VERSION ""

NS_ :

BS_:

BU_: ADTF
VAL_TABLE_ State_RPA_START_SCcnt1 171 "FS_RPA_LISTEN_MSG_CHECK" 107 "FS_RPA_LISTEN_KG_ENABLE" 59 "FS_RPA_PAIRING_SC" 51 "FS_RPA_LISTEN_TERMINATED_SC" 43 "FS_RPA_LISTEN_SC" 35 "FS_RPA_IDLE_SC" 27 "FS_RPA_IDLE_OUTSIDE_WAIT" 19 "FS_RPA_DIALOG_SC" 11 "FS_RPA_ACTIVATED_SC" 5 "FS_DefaultOf_RPA_START_SCst2" 2 "FS_STATE_22st4" 1 "FS_RPA_START_SCst2" 0 "FS_Chart_RPA_START_SC" ;
VAL_TABLE_ State_RPA_INSIDE_ACTIVE_SC 1931 "DefaultOf_RPA_ACTIV_MAN_FROM_INS" 1675 "FS_RPA_INSIDE_UNDO_CONTINUE" 1419 "FS_RPA_INSIDE_ACTIVE_UNDO" 1163 "FS_RPA_INSIDE_ACTIVE_TAKE_OVER" 907 "FS_RPA_INSIDE_ACTIVE_RECONNECT" 651 "FS_RPA_INSIDE_ACTIVE_MANEUVER_SC" 395 "FS_RPA_INSIDE_ACTIVE_CONTINUE_SC" 203 "RPA_WAIT_EIS_ACTIVATION_FROM_INS" 155 "FS_RPA_MENU_INSIDE_MANEUVER" 139 "RPA_ACTIVATE_MANEUVER_FROM_IN" 91 "FS_RPA_MENU_ADJUST_START" 75 "FS_RPA_ACTIVATE_EIS_FROM_INSIDE" 51 "FS_RPA_WAIT_INSIDE_SC" 43 "FS_RPA_UNDO_INSIDE_GET_P2_READY" 35 "FS_RPA_PARK_INSIDE_SC" 27 "FS_RPA_MENU_INSIDE_SC" 19 "FS_RPA_INSIDE_UNDO_WAIT" 11 "FS_RPA_INIT_INSIDE_SC" 5 "FS_DefaultOf_RPA_ACTIVE_FROM_INS" 3 "FS_STATE_22st5" 1 "FS_RPA_ACTIVE_FROM_INSIDE" 0 "FS_Chart_RPA_INSIDE_ACTIVE_SC" ;
VAL_TABLE_ RPA_OUTSIDE_ACTIVE_SC 1675 "Default_RPA_ACTIV_MANEU_FR_OUT" 1419 "FS_RPA_OUTSIDE_UNDO_CONTINUE" 1163 "FS_RPA_OUTSIDE_CONTINUE_SC" 907 "FS_RPA_OUTSIDE_ACTIVE_UNDO" 651 "FS_RPA_OUTSIDE_ACTIVE_RECONNECT" 395 "FS_RPA_OUTSIDE_ACTIVE_MANEUVER" 201 "FS_RPA_WAIT_EIS_ACTIV_FROM_OUT" 179 "FS_WAIT_OUTSIDE_RDY" 139 "RPA_ACTIVATE_MANEUVER_FROM_OUTS" 115 "FS_WAIT_OUTSIDE_PADH" 75 "FS_RPA_ACTIVATE_EIS_FROM_OUTSIDE" 51 "FS_RPA_WAIT_OUSIDE" 43 "FS_RPA_UNDO_OUTSIDE_GET_P2_READY" 35 "FS_RPA_PARK_OUTSIDE_SC" 27 "FS_RPA_OUTSIDE_UNDO_WAIT" 19 "FS_RPA_MENU_OUTSIDE_SC" 11 "FS_RPA_INIT_OUTSIDE_SC" 5 "FS_DefaultOf_RPA_ACTIVE_FROM_OUT" 3 "FS_STATE_20st6" 1 "FS_RPA_ACTIVE_FROM_OUTSIDE" 0 "FS_Chart_RPA_OUTSIDE_ACTIVE_SC" ;
VAL_TABLE_ currentState_RPA_END_SCcnt1 955 "FS_RPA_WAIT_P2_TERMINATE" 827 "FS_RPA_WAIT_P2_STEERING_FINISH" 699 "FS_RPA_WAIT_P2_ABORT" 571 "FS_RPA_NO_CONTINUE" 443 "FS_RPA_NORMAL_TERMINATE" 315 "FS_RPA_MANEUVER_TERMINATE" 267 "FS_RPA_CANCEL_STEERING_AND_BRAKE" 187 "FS_RPA_ERROR_TERMINATE" 139 "FS_RPA_CANCEL_EIS" 67 "FS_RPA_WAS_ACTIVE" 59 "FS_RPA_TERMINATE_SC" 51 "FS_RPA_RECONNECT_POSSIBLE" 43 "FS_RPA_KG_FINISH" 27 "FS_RPA_EIS_FINISH" 19 "FS_RPA_CONTINUE_POSSIBLE" 17 "FS_RPA_CANCEL_SC" 5 "FS_DefaultOf_RPA_END_SCst2" 3 "FS_STATE_29st3" 1 "FS_RPA_END_SCst2" 0 "FS_Chart_RPA_END_SC" ;
VAL_TABLE_ Tbl_ACTL_RemCtrlPark_Maneuver3 17 "RTE_PARK_INVALID" 16 "RTE_EXPLORATION_MODE" 15 "RTE_PARK_OUT_PERP_LEFT_BACKWARD" 14 "RTE_PARK_OUT_PERP_LEFT_FORWARD" 13 "RTE_PARK_OUT_PERP_RIGHT_BACKWARD" 12 "RTE_PARK_OUT_PERP_RIGHT_FORWARD" 11 "RTE_PARK_OUT_PARA_LEFT_BACKWARD" 10 "RTE_PARK_OUT_PARA_LEFT_FORWARD" 9 "RTE_PARK_OUT_PARA_RIGHT_BACKWARD" 8 "RTE_PARK_OUT_PARA_RIGHT_FORWARD" 7 "RTE_PARK_IN_PERP_LEFT_BACWARD" 6 "RTE_PARK_IN_PERP_LEFT_FORWARD" 5 "RTE_PARK_IN_PERP_RIGHT_BACKWARD" 4 "RTE_PARK_IN_PERP_RIGHT_FORWARD" 3 "RTE_PARK_IN_PARA_LEFT_BACKWARD" 2 "RTE_PARK_IN_PARA_LEFT_FORWARD" 1 "RTE_PARK_IN_PARA_RIGHT_BACKWARD" 0 "RTE_PARK_IN_PARA_RIGHT_FORWARD" ;
VAL_TABLE_ Tbl_ACTL_RemCtrlPark_Maneuver2 17 "RTE_PARK_INVALID" 16 "RTE_EXPLORATION_MODE" 15 "RTE_PARK_OUT_PERP_LEFT_BACKWARD" 14 "RTE_PARK_OUT_PERP_LEFT_FORWARD" 13 "RTE_PARK_OUT_PERP_RIGHT_BACKWARD" 12 "RTE_PARK_OUT_PERP_RIGHT_FORWARD" 11 "RTE_PARK_OUT_PARA_LEFT_BACKWARD" 10 "RTE_PARK_OUT_PARA_LEFT_FORWARD" 9 "RTE_PARK_OUT_PARA_RIGHT_BACKWARD" 8 "RTE_PARK_OUT_PARA_RIGHT_FORWARD" 7 "RTE_PARK_IN_PERP_LEFT_BACWARD" 6 "RTE_PARK_IN_PERP_LEFT_FORWARD" 5 "RTE_PARK_IN_PERP_RIGHT_BACKWARD" 4 "RTE_PARK_IN_PERP_RIGHT_FORWARD" 3 "RTE_PARK_IN_PARA_LEFT_BACKWARD" 2 "RTE_PARK_IN_PARA_LEFT_FORWARD" 1 "RTE_PARK_IN_PARA_RIGHT_BACKWARD" 0 "RTE_PARK_IN_PARA_RIGHT_FORWARD" ;
VAL_TABLE_ Tbl_ACTL_RemCtrlPark_Maneuvers 17 "RTE_PARK_INVALID" 16 "RTE_EXPLORATION_MODE" 15 "RTE_PARK_OUT_PERP_LEFT_BACKWARD" 14 "RTE_PARK_OUT_PERP_LEFT_FORWARD" 13 "RTE_PARK_OUT_PERP_RIGHT_BACKWARD" 12 "RTE_PARK_OUT_PERP_RIGHT_FORWARD" 11 "RTE_PARK_OUT_PARA_LEFT_BACKWARD" 10 "RTE_PARK_OUT_PARA_LEFT_FORWARD" 9 "RTE_PARK_OUT_PARA_RIGHT_BACKWARD" 8 "RTE_PARK_OUT_PARA_RIGHT_FORWARD" 7 "RTE_PARK_IN_PERP_LEFT_BACWARD" 6 "RTE_PARK_IN_PERP_LEFT_FORWARD" 5 "RTE_PARK_IN_PERP_RIGHT_BACKWARD" 4 "RTE_PARK_IN_PERP_RIGHT_FORWARD" 3 "RTE_PARK_IN_PARA_LEFT_BACKWARD" 2 "RTE_PARK_IN_PARA_LEFT_FORWARD" 1 "RTE_PARK_IN_PARA_RIGHT_BACKWARD" 0 "RTE_PARK_IN_PARA_RIGHT_FORWARD" ;
VAL_TABLE_ Tbl_ACTL_RemCtrlPark_MsgID 31 "RTE_MSG_TARGET_POS_CORRECT" 30 "RTE_MSG_OLD_APP_VER" 29 "RTE_MSG_OLD_APP_VER_3" 28 "RTE_MSG_OLD_APP_VER_2" 27 "RTE_MSG_OLD_APP_VER_1" 26 "RTE_MSG_WRONG_APP_VER_0" 25 "RTE_MSG_INCOMP" 24 "RTE_MSG_COM_NO_AUTH" 23 "RTE_MSG_COM_ERR" 22 "RTE_MSG_COM_NO_DEV" 21 "RTE_MSG_COM_NO_BT" 20 "RTE_MSG_COM_BT_OFF" 19 "RTE_MSG_NARROW_DIST" 18 "RTE_MSG_BATTERY" 17 "RTE_MSG_TRAILER" 16 "RTE_MSG_OBSTACLE" 15 "RTE_MSG_SLOPE" 14 "RTE_MSG_ASR" 13 "RTE_MSG_NO_P" 12 "RTE_MSG_ACT_DRV" 11 "RTE_MSG_DOOR_OPENED" 10 "RTE_MSG_BELT_LOCKED" 9 "RTE_MSG_KEY_ACTUATED" 8 "RTE_MSG_KEY_INSIDE_DETECTED" 7 "RTE_MSG_KEY_NOT_DETECTED" 6 "RTE_MSG_CONNECT_ERROR" 5 "RTE_MSG_SYS_ERROR" 4 "RTE_MSG_END_TURN_REACHED" 3 "RTE_MSG_MAX_DIST" 2 "RTE_MSG_TARGET_POS_REACHED" 1 "RTE_MSG_RPA_TERMINATED" 0 "RTE_MSG_NONE" ;
VAL_TABLE_ Tbl_ACTL_RemCtrlPark_CurrGear 8 "RTE_RMC_GEAR_PARK" 7 "RTE_RMC_GEAR_REVERSE" 6 "RTE_RMC_GEAR_NEUTRAL" 5 "RTE_RMC_GEAR_DRIVE" 0 "RTE_RMC_GEAR_IDLE" ;
VAL_TABLE_ Tbl_ACTL_RemCtrlP_CurrRpaMode 9 "RTE_RPA_TERMINATING" 8 "RTE_RPA_CANCEL" 7 "RTE_RPA_PARK" 6 "RTE_RPA_MENU" 5 "RTE_RPA_INIT" 4 "RTE_RPA_WAIT" 3 "RTE_RPA_LISTEN" 2 "RTE_RPA_DIALOG" 1 "RTE_RPA_PAIRING" 0 "RTE_RPA_IDLE" ;
VAL_TABLE_ Tbl_LastRcFrameType 255 "RTE_RMC_RC_FRAME_UNKNOW " 5 "RTE_RMC_RC_FRAME_DEVICE_NAME " 4 "RTE_RMC_RC_FRAME_ERROR " 3 "RTE_RMC_RC_FRAME_ACTIVE " 2 "RTE_RMC_RC_FRAME_SW_VER" 1 "RTE_RMC_RC_FRAME_HW_VER " 0 "RTE_RMC_RC_FRAME_SECURITY " ;
VAL_TABLE_ Tbl_IsRmcActive 3 "RTE_RMC_BLE_RECEIVER_PAIRING " 2 "RTE_RMC_BLE_RECEIVER_CONNECTED" 1 "RTE_RMC_BLE_RECEIVER_ACTIVE " 0 "RTE_RMC_BLE_RECEIVER_NOT_ACTIVE " ;
VAL_TABLE_ Tbl_RMC_GestureState 170 "RTE_RMC_GESTURE_ST_VALID" 85 "RTE_RMC_GESTURE_ST_NOT_VALID " ;
VAL_TABLE_ Tbl_RMC_SelectedGear 8 "RTE_RMC_GEAR_PARK " 7 "RTE_RMC_GEAR_REVERSE " 6 "RTE_RMC_GEAR_NEUTRAL " 5 "RTE_RMC_GEAR_DRIVE " 0 "RTE_RMC_GEAR_IDLE " ;
VAL_TABLE_ Tbl_RMC_DeadManSwitch 170 "RTE_RMC_DMS_ST_VALID " 85 "RTE_RMC_DMS_ST_NOT_VALID" ;
VAL_TABLE_ Tbl_RmcState 9 "RTE_RMC_APP_ST_ERROR " 8 "RTE_RMC_APP_ST_TERMINATING" 7 "RTE_RMC_APP_ST_MESSAGE " 6 "RTE_RMC_APP_ST_PARK " 5 "RTE_RMC_APP_ST_INTERRUPT " 4 "RTE_RMC_APP_ST_MENU " 3 "RTE_RMC_APP_ST_INIT " 2 "RTE_RMC_APP_ST_WAIT " 1 "RTE_RMC_APP_ST_CONNECTING " 0 "RTE_RMC_APP_ST_IDLE " ;
VAL_TABLE_ Tbl_currState_aRPA_ACT_F_OUT_SC 1419 "FS_DefauOf_RPA_ACTIV_MAN_FR_OUT" 5 "FS_DefaultOf_RPA_ACTIVE_FROM_OUT" 171 "FS_WAIT_OUTSIDE_RDY " 107 "FS_WAIT_OUTSIDE_PADH " 43 "FS_RPA_WAIT_OUTSIDE_SC " 35 "FS_RPA_UNDO_OUT_GET_P2_READY " 27 "FS_RPA_PARK_OUTSIDE_SC " 19 "FS_RPA_MENU_OUT_SC " 203 "FS_RPA_WAIT_EIS_ACTIV_FR_OUT" 1163 "FS_RPA_OUTSIDE_CONTINUE_SC " 907 "FS_RPA_OUT_ACTIVE_UNDO " 651 "FS_RPA_OUT_ACTIV_RECONNECT_SC " 395 "FS_RPA_OUT_ACTIV_MANEUVER_SC " 139 "FS_RPA_ACTIVATE_MAN_FROM_OUT" 75 "FS_RPA_ACTIVATE_EIS_FROM_OUT" 11 "FS_RPA_INIT_OUT_SC" 3 "FS_STATE_18st6" 1 "FS_RPA_ACTIVE_FROM_OUT" 0 "FS_Chart_RPA_OUT_ACTIVE_SC " ;

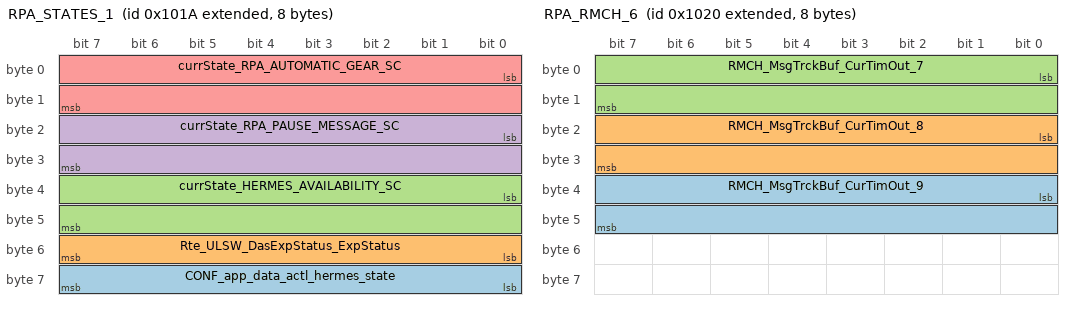
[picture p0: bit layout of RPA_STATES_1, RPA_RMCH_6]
BO_ 2147487770 RPA_STATES_1: 8 ADTF
 SG_ CONF_app_data_actl_hermes_state : 56|8@1+ (1,0) [0|0] "" Vector__XXX
 SG_ Rte_ULSW_DasExpStatus_ExpStatus : 48|8@1+ (1,0) [0|0] "" Vector__XXX
 SG_ currState_HERMES_AVAILABILITY_SC : 32|16@1+ (1,0) [0|0] "" Vector__XXX
 SG_ currState_RPA_PAUSE_MESSAGE_SC : 16|16@1+ (1,0) [0|0] "" Vector__XXX
 SG_ currState_RPA_AUTOMATIC_GEAR_SC : 0|16@1+ (1,0) [0|0] "" Vector__XXX

BO_ 2147487776 RPA_RMCH_6: 8 ADTF
 SG_ RMCH_MsgTrckBuf_CurTimOut_9 : 32|16@1+ (1,0) [0|0] "" Vector__XXX
 SG_ RMCH_MsgTrckBuf_CurTimOut_8 : 16|16@1+ (1,0) [0|0] "" Vector__XXX
 SG_ RMCH_MsgTrckBuf_CurTimOut_7 : 0|16@1+ (1,0) [0|0] "" Vector__XXX

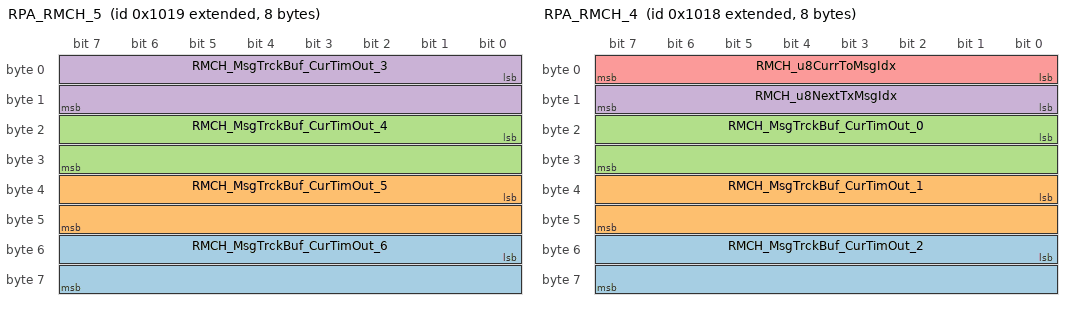
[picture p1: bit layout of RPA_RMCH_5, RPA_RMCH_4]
BO_ 2147487769 RPA_RMCH_5: 8 ADTF
 SG_ RMCH_MsgTrckBuf_CurTimOut_6 : 48|16@1+ (1,0) [0|0] "" Vector__XXX
 SG_ RMCH_MsgTrckBuf_CurTimOut_5 : 32|16@1+ (1,0) [0|0] "" Vector__XXX
 SG_ RMCH_MsgTrckBuf_CurTimOut_4 : 16|16@1+ (1,0) [0|0] "" Vector__XXX
 SG_ RMCH_MsgTrckBuf_CurTimOut_3 : 0|16@1+ (1,0) [0|0] "" Vector__XXX

BO_ 2147487768 RPA_RMCH_4: 8 ADTF
 SG_ RMCH_MsgTrckBuf_CurTimOut_2 : 48|16@1+ (1,0) [0|0] "" Vector__XXX
 SG_ RMCH_MsgTrckBuf_CurTimOut_1 : 32|16@1+ (1,0) [0|0] "" Vector__XXX
 SG_ RMCH_MsgTrckBuf_CurTimOut_0 : 16|16@1+ (1,0) [0|0] "" Vector__XXX
 SG_ RMCH_u8NextTxMsgIdx : 8|8@1+ (1,0) [0|0] "" Vector__XXX
 SG_ RMCH_u8CurrToMsgIdx : 0|8@1+ (1,0) [0|0] "" Vector__XXX

BO_ 2147487767 RPA_RMCH_3: 8 ADTF
 SG_ RMCH_u32SessionCounter : 32|32@1+ (1,0) [0|0] "" Vector__XXX
 SG_ RMCH_u32LastSentTime : 0|32@1+ (1,0) [0|0] "" Vector__XXX

BO_ 2147487762 RPA_ACTL_2: 8 ADTF
 SG_ currState_RPA_END_SCcnt1 : 0|32@1+ (1,0) [0|0] "ms" Vector__XXX

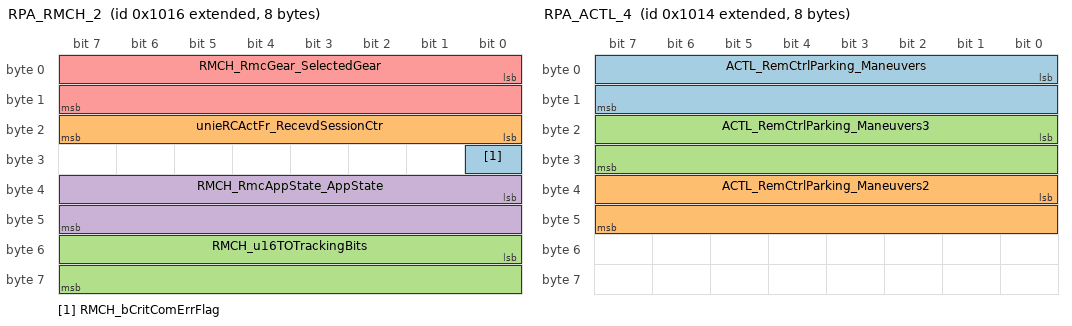
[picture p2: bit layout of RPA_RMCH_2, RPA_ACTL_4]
BO_ 2147487766 RPA_RMCH_2: 8 ADTF
 SG_ RMCH_bCritComErrFlag : 24|1@1+ (1,0) [0|0] "" Vector__XXX
 SG_ unieRCActFr_RecevdSessionCtr : 16|8@1+ (1,0) [0|0] "" Vector__XXX
 SG_ RMCH_u16TOTrackingBits : 48|16@1+ (1,0) [0|0] "" Vector__XXX
 SG_ RMCH_RmcAppState_AppState : 32|16@1+ (1,0) [0|0] "" Vector__XXX
 SG_ RMCH_RmcGear_SelectedGear : 0|16@1+ (1,0) [0|0] "" Vector__XXX

BO_ 2147487764 RPA_ACTL_4: 8 ADTF
 SG_ ACTL_RemCtrlParking_Maneuvers : 0|16@1+ (1,0) [0|0] "ms" Vector__XXX
 SG_ ACTL_RemCtrlParking_Maneuvers2 : 32|16@1+ (1,0) [0|0] "ms" Vector__XXX
 SG_ ACTL_RemCtrlParking_Maneuvers3 : 16|16@1+ (1,0) [0|0] "ms" Vector__XXX

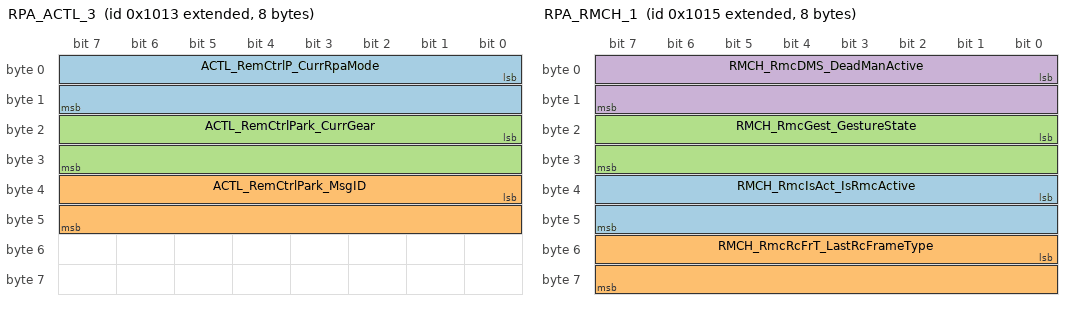
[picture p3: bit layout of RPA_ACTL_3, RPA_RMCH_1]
BO_ 2147487763 RPA_ACTL_3: 8 ADTF
 SG_ ACTL_RemCtrlP_CurrRpaMode : 0|16@1+ (1,0) [0|0] "" Vector__XXX
 SG_ ACTL_RemCtrlPark_MsgID : 32|16@1+ (1,0) [0|0] "ms" Vector__XXX
 SG_ ACTL_RemCtrlPark_CurrGear : 16|16@1+ (1,0) [0|0] "ms" Vector__XXX

BO_ 2147487765 RPA_RMCH_1: 8 ADTF
 SG_ RMCH_RmcIsAct_IsRmcActive : 32|16@1+ (1,0) [0|0] "" Vector__XXX
 SG_ RMCH_RmcRcFrT_LastRcFrameType : 48|16@1+ (1,0) [0|0] "ms" Vector__XXX
 SG_ RMCH_RmcGest_GestureState : 16|16@1+ (1,0) [0|0] "" Vector__XXX
 SG_ RMCH_RmcDMS_DeadManActive : 0|16@1+ (1,0) [0|0] "" Vector__XXX

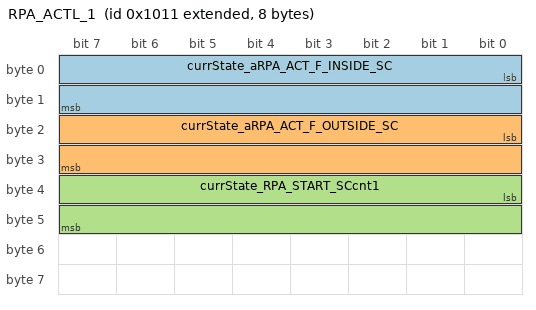
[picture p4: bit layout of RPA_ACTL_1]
BO_ 2147487761 RPA_ACTL_1: 8 ADTF
 SG_ currState_aRPA_ACT_F_INSIDE_SC : 0|16@1+ (1,0) [0|0] "ms" Vector__XXX
 SG_ currState_aRPA_ACT_F_OUTSIDE_SC : 16|16@1+ (1,0) [0|0] "ms" Vector__XXX
 SG_ currState_RPA_START_SCcnt1 : 32|16@1+ (1,0) [0|0] "ms" Vector__XXX

CM_ SG_ 2147487762 currState_RPA_END_SCcnt1 "Current state of ACTL state machine if system was finished. Autogenerated.
 Variable name and value subject to uncontrolled changes. 
Size can vary from u8 to u32 depending on states & transitions count";
CM_ SG_ 2147487766 RMCH_RmcAppState_AppState "is part of the proposed last BLE frame";
CM_ SG_ 2147487766 RMCH_RmcGear_SelectedGear "Selected gear on smartphone";
CM_ SG_ 2147487764 ACTL_RemCtrlParking_Maneuvers "Buffer of the max 3 offered maneuver";
CM_ SG_ 2147487764 ACTL_RemCtrlParking_Maneuvers2 "Buffer of the max 3 offered maneuver";
CM_ SG_ 2147487764 ACTL_RemCtrlParking_Maneuvers3 "Buffer of the max 3 offered maneuver";
CM_ SG_ 2147487763 ACTL_RemCtrlP_CurrRpaMode "Listen, Choice, Active";
CM_ SG_ 2147487763 ACTL_RemCtrlPark_MsgID "MsgId sent from Logic to Smartphone to trigger a specific message";
CM_ SG_ 2147487763 ACTL_RemCtrlPark_CurrGear "Current gear of the car";
CM_ SG_ 2147487765 RMCH_RmcIsAct_IsRmcActive "Indication that ECU and smartphone are connected";
CM_ SG_ 2147487765 RMCH_RmcRcFrT_LastRcFrameType "Includes AppState";
CM_ SG_ 2147487765 RMCH_RmcGest_GestureState "Bit to indicate if confirmation gesture is valid/finished from ECU";
CM_ SG_ 2147487765 RMCH_RmcDMS_DeadManActive "Bit to indicate if deadman gesture is valid/active from ECU";
CM_ SG_ 2147487761 currState_aRPA_ACT_F_INSIDE_SC "Current state of ACTL state machine if system was activated from inside. Autogenerated. 
Variable name and value subject to uncontrolled changes. 
Size can vary from u8 to u32 depending on states & transitions count";
CM_ SG_ 2147487761 currState_aRPA_ACT_F_OUTSIDE_SC "Current state of ACTL state machine if system was activated from inside. Autogenerated.
 Variable name and value subject to uncontrolled changes. 
Size can vary from u8 to u32 depending on states & transitions count";
CM_ SG_ 2147487761 currState_RPA_START_SCcnt1 "Current state of ACTL state machine Listen/Choice. Autogenerated. Variable name and value subject to uncontrolled changes. Size can vary from u8 to u32 depending on states & transitions count";
VAL_ 2147487762 currState_RPA_END_SCcnt1 955 "FS_RPA_WAIT_P2_TERMINATE" 827 "FS_RPA_WAIT_P2_STEERING_FINISH" 699 "FS_RPA_WAIT_P2_ABORT" 571 "FS_RPA_NO_CONTINUE" 443 "FS_RPA_NORMAL_TERMINATE" 315 "FS_RPA_MANEUVER_TERMINATE" 267 "FS_RPA_CANCEL_STEERING_AND_BRAKE" 187 "FS_RPA_ERROR_TERMINATE" 139 "FS_RPA_CANCEL_EIS" 67 "FS_RPA_WAS_ACTIVE" 59 "FS_RPA_TERMINATE_SC" 51 "FS_RPA_RECONNECT_POSSIBLE" 43 "FS_RPA_KG_FINISH" 27 "FS_RPA_EIS_FINISH" 19 "FS_RPA_CONTINUE_POSSIBLE" 17 "FS_RPA_CANCEL_SC" 5 "FS_DefaultOf_RPA_END_SCst2" 3 "FS_STATE_29st3" 1 "FS_RPA_END_SCst2" 0 "FS_Chart_RPA_END_SC" ;
VAL_ 2147487766 RMCH_RmcAppState_AppState 9 "RTE_RMC_APP_ST_ERROR " 8 "RTE_RMC_APP_ST_TERMINATING" 7 "RTE_RMC_APP_ST_MESSAGE " 6 "RTE_RMC_APP_ST_PARK " 5 "RTE_RMC_APP_ST_INTERRUPT " 4 "RTE_RMC_APP_ST_MENU " 3 "RTE_RMC_APP_ST_INIT " 2 "RTE_RMC_APP_ST_WAIT " 1 "RTE_RMC_APP_ST_CONNECTING " 0 "RTE_RMC_APP_ST_IDLE " ;
VAL_ 2147487766 RMCH_RmcGear_SelectedGear 8 "RTE_RMC_GEAR_PARK " 7 "RTE_RMC_GEAR_REVERSE " 6 "RTE_RMC_GEAR_NEUTRAL " 5 "RTE_RMC_GEAR_DRIVE " 0 "RTE_RMC_GEAR_IDLE " ;
VAL_ 2147487764 ACTL_RemCtrlParking_Maneuvers 17 "RTE_PARK_INVALID" 16 "RTE_EXPLORATION_MODE" 15 "RTE_PARK_OUT_PERP_LEFT_BACKWARD" 14 "RTE_PARK_OUT_PERP_LEFT_FORWARD" 13 "RTE_PARK_OUT_PERP_RIGHT_BACKWARD" 12 "RTE_PARK_OUT_PERP_RIGHT_FORWARD" 11 "RTE_PARK_OUT_PARA_LEFT_BACKWARD" 10 "RTE_PARK_OUT_PARA_LEFT_FORWARD" 9 "RTE_PARK_OUT_PARA_RIGHT_BACKWARD" 8 "RTE_PARK_OUT_PARA_RIGHT_FORWARD" 7 "RTE_PARK_IN_PERP_LEFT_BACWARD" 6 "RTE_PARK_IN_PERP_LEFT_FORWARD" 5 "RTE_PARK_IN_PERP_RIGHT_BACKWARD" 4 "RTE_PARK_IN_PERP_RIGHT_FORWARD" 3 "RTE_PARK_IN_PARA_LEFT_BACKWARD" 2 "RTE_PARK_IN_PARA_LEFT_FORWARD" 1 "RTE_PARK_IN_PARA_RIGHT_BACKWARD" 0 "RTE_PARK_IN_PARA_RIGHT_FORWARD" ;
VAL_ 2147487764 ACTL_RemCtrlParking_Maneuvers2 17 "RTE_PARK_INVALID" 16 "RTE_EXPLORATION_MODE" 15 "RTE_PARK_OUT_PERP_LEFT_BACKWARD" 14 "RTE_PARK_OUT_PERP_LEFT_FORWARD" 13 "RTE_PARK_OUT_PERP_RIGHT_BACKWARD" 12 "RTE_PARK_OUT_PERP_RIGHT_FORWARD" 11 "RTE_PARK_OUT_PARA_LEFT_BACKWARD" 10 "RTE_PARK_OUT_PARA_LEFT_FORWARD" 9 "RTE_PARK_OUT_PARA_RIGHT_BACKWARD" 8 "RTE_PARK_OUT_PARA_RIGHT_FORWARD" 7 "RTE_PARK_IN_PERP_LEFT_BACWARD" 6 "RTE_PARK_IN_PERP_LEFT_FORWARD" 5 "RTE_PARK_IN_PERP_RIGHT_BACKWARD" 4 "RTE_PARK_IN_PERP_RIGHT_FORWARD" 3 "RTE_PARK_IN_PARA_LEFT_BACKWARD" 2 "RTE_PARK_IN_PARA_LEFT_FORWARD" 1 "RTE_PARK_IN_PARA_RIGHT_BACKWARD" 0 "RTE_PARK_IN_PARA_RIGHT_FORWARD" ;
VAL_ 2147487764 ACTL_RemCtrlParking_Maneuvers3 17 "RTE_PARK_INVALID" 16 "RTE_EXPLORATION_MODE" 15 "RTE_PARK_OUT_PERP_LEFT_BACKWARD" 14 "RTE_PARK_OUT_PERP_LEFT_FORWARD" 13 "RTE_PARK_OUT_PERP_RIGHT_BACKWARD" 12 "RTE_PARK_OUT_PERP_RIGHT_FORWARD" 11 "RTE_PARK_OUT_PARA_LEFT_BACKWARD" 10 "RTE_PARK_OUT_PARA_LEFT_FORWARD" 9 "RTE_PARK_OUT_PARA_RIGHT_BACKWARD" 8 "RTE_PARK_OUT_PARA_RIGHT_FORWARD" 7 "RTE_PARK_IN_PERP_LEFT_BACWARD" 6 "RTE_PARK_IN_PERP_LEFT_FORWARD" 5 "RTE_PARK_IN_PERP_RIGHT_BACKWARD" 4 "RTE_PARK_IN_PERP_RIGHT_FORWARD" 3 "RTE_PARK_IN_PARA_LEFT_BACKWARD" 2 "RTE_PARK_IN_PARA_LEFT_FORWARD" 1 "RTE_PARK_IN_PARA_RIGHT_BACKWARD" 0 "RTE_PARK_IN_PARA_RIGHT_FORWARD" ;
VAL_ 2147487763 ACTL_RemCtrlP_CurrRpaMode 9 "RTE_RPA_TERMINATING" 8 "RTE_RPA_CANCEL" 7 "RTE_RPA_PARK" 6 "RTE_RPA_MENU" 5 "RTE_RPA_INIT" 4 "RTE_RPA_WAIT" 3 "RTE_RPA_LISTEN" 2 "RTE_RPA_DIALOG" 1 "RTE_RPA_PAIRING" 0 "RTE_RPA_IDLE" ;
VAL_ 2147487763 ACTL_RemCtrlPark_MsgID 31 "RTE_MSG_TARGET_POS_CORRECT" 30 "RTE_MSG_OLD_APP_VER" 29 "RTE_MSG_OLD_APP_VER_3" 28 "RTE_MSG_OLD_APP_VER_2" 27 "RTE_MSG_OLD_APP_VER_1" 26 "RTE_MSG_WRONG_APP_VER_0" 25 "RTE_MSG_INCOMP" 24 "RTE_MSG_COM_NO_AUTH" 23 "RTE_MSG_COM_ERR" 22 "RTE_MSG_COM_NO_DEV" 21 "RTE_MSG_COM_NO_BT" 20 "RTE_MSG_COM_BT_OFF" 19 "RTE_MSG_NARROW_DIST" 18 "RTE_MSG_BATTERY" 17 "RTE_MSG_TRAILER" 16 "RTE_MSG_OBSTACLE" 15 "RTE_MSG_SLOPE" 14 "RTE_MSG_ASR" 13 "RTE_MSG_NO_P" 12 "RTE_MSG_ACT_DRV" 11 "RTE_MSG_DOOR_OPENED" 10 "RTE_MSG_BELT_LOCKED" 9 "RTE_MSG_KEY_ACTUATED" 8 "RTE_MSG_KEY_INSIDE_DETECTED" 7 "RTE_MSG_KEY_NOT_DETECTED" 6 "RTE_MSG_CONNECT_ERROR" 5 "RTE_MSG_SYS_ERROR" 4 "RTE_MSG_END_TURN_REACHED" 3 "RTE_MSG_MAX_DIST" 2 "RTE_MSG_TARGET_POS_REACHED" 1 "RTE_MSG_RPA_TERMINATED" 0 "RTE_MSG_NONE" ;
VAL_ 2147487763 ACTL_RemCtrlPark_CurrGear 8 "RTE_RMC_GEAR_PARK" 7 "RTE_RMC_GEAR_REVERSE" 6 "RTE_RMC_GEAR_NEUTRAL" 5 "RTE_RMC_GEAR_DRIVE" 0 "RTE_RMC_GEAR_IDLE" ;
VAL_ 2147487765 RMCH_RmcIsAct_IsRmcActive 3 "RTE_RMC_BLE_RECEIVER_PAIRING " 2 "RTE_RMC_BLE_RECEIVER_CONNECTED" 1 "RTE_RMC_BLE_RECEIVER_ACTIVE " 0 "RTE_RMC_BLE_RECEIVER_NOT_ACTIVE " ;
VAL_ 2147487765 RMCH_RmcRcFrT_LastRcFrameType 255 "RTE_RMC_RC_FRAME_UNKNOW " 5 "RTE_RMC_RC_FRAME_DEVICE_NAME " 4 "RTE_RMC_RC_FRAME_ERROR " 3 "RTE_RMC_RC_FRAME_ACTIVE " 2 "RTE_RMC_RC_FRAME_SW_VER" 1 "RTE_RMC_RC_FRAME_HW_VER " 0 "RTE_RMC_RC_FRAME_SECURITY " ;
VAL_ 2147487765 RMCH_RmcGest_GestureState 170 "RTE_RMC_GESTURE_ST_VALID" 85 "RTE_RMC_GESTURE_ST_NOT_VALID " ;
VAL_ 2147487765 RMCH_RmcDMS_DeadManActive 170 "RTE_RMC_DMS_ST_VALID " 85 "RTE_RMC_DMS_ST_NOT_VALID" ;
VAL_ 2147487761 currState_aRPA_ACT_F_INSIDE_SC 1931 "DefaultOf_RPA_ACTIV_MAN_FROM_INS" 1675 "FS_RPA_INSIDE_UNDO_CONTINUE" 1419 "FS_RPA_INSIDE_ACTIVE_UNDO" 1163 "FS_RPA_INSIDE_ACTIVE_TAKE_OVER" 907 "FS_RPA_INSIDE_ACTIVE_RECONNECT" 651 "FS_RPA_INSIDE_ACTIVE_MANEUVER_SC" 395 "FS_RPA_INSIDE_ACTIVE_CONTINUE_SC" 203 "RPA_WAIT_EIS_ACTIVATION_FROM_INS" 155 "FS_RPA_MENU_INSIDE_MANEUVER" 139 "RPA_ACTIVATE_MANEUVER_FROM_IN" 91 "FS_RPA_MENU_ADJUST_START" 75 "FS_RPA_ACTIVATE_EIS_FROM_INSIDE" 51 "FS_RPA_WAIT_INSIDE_SC" 43 "FS_RPA_UNDO_INSIDE_GET_P2_READY" 35 "FS_RPA_PARK_INSIDE_SC" 27 "FS_RPA_MENU_INSIDE_SC" 19 "FS_RPA_INSIDE_UNDO_WAIT" 11 "FS_RPA_INIT_INSIDE_SC" 5 "FS_DefaultOf_RPA_ACTIVE_FROM_INS" 3 "FS_STATE_22st5" 1 "FS_RPA_ACTIVE_FROM_INSIDE" 0 "FS_Chart_RPA_INSIDE_ACTIVE_SC" ;
VAL_ 2147487761 currState_aRPA_ACT_F_OUTSIDE_SC 1675 "Default_RPA_ACTIV_MANEU_FR_OUT" 1419 "FS_RPA_OUTSIDE_UNDO_CONTINUE" 1163 "FS_RPA_OUTSIDE_CONTINUE_SC" 907 "FS_RPA_OUTSIDE_ACTIVE_UNDO" 651 "FS_RPA_OUTSIDE_ACTIVE_RECONNECT" 395 "FS_RPA_OUTSIDE_ACTIVE_MANEUVER" 201 "FS_RPA_WAIT_EIS_ACTIV_FROM_OUT" 179 "FS_WAIT_OUTSIDE_RDY" 139 "RPA_ACTIVATE_MANEUVER_FROM_OUTS" 115 "FS_WAIT_OUTSIDE_PADH" 75 "FS_RPA_ACTIVATE_EIS_FROM_OUTSIDE" 51 "FS_RPA_WAIT_OUSIDE" 43 "FS_RPA_UNDO_OUTSIDE_GET_P2_READY" 35 "FS_RPA_PARK_OUTSIDE_SC" 27 "FS_RPA_OUTSIDE_UNDO_WAIT" 19 "FS_RPA_MENU_OUTSIDE_SC" 11 "FS_RPA_INIT_OUTSIDE_SC" 5 "FS_DefaultOf_RPA_ACTIVE_FROM_OUT" 3 "FS_STATE_20st6" 1 "FS_RPA_ACTIVE_FROM_OUTSIDE" 0 "FS_Chart_RPA_OUTSIDE_ACTIVE_SC" ;
VAL_ 2147487761 currState_RPA_START_SCcnt1 171 "FS_RPA_LISTEN_MSG_CHECK" 107 "FS_RPA_LISTEN_KG_ENABLE" 59 "FS_RPA_PAIRING_SC" 51 "FS_RPA_LISTEN_TERMINATED_SC" 43 "FS_RPA_LISTEN_SC" 35 "FS_RPA_IDLE_SC" 27 "FS_RPA_IDLE_OUTSIDE_WAIT" 19 "FS_RPA_DIALOG_SC" 11 "FS_RPA_ACTIVATED_SC" 5 "FS_DefaultOf_RPA_START_SCst2" 2 "FS_STATE_22st4" 1 "FS_RPA_START_SCst2" 0 "FS_Chart_RPA_START_SC" ;
